# M251_v1 register map
File version: 1.0
Registers are 32-bit, read-write, reset 0x0 unless marked. A register's access mark holds for its fields unless they carry their own. Offsets are from the block's base; [hi:lo] are bit positions; {n}, {i} and the like mark numbered series.

## FMC — FMC Register Map
Base 0x4000C000
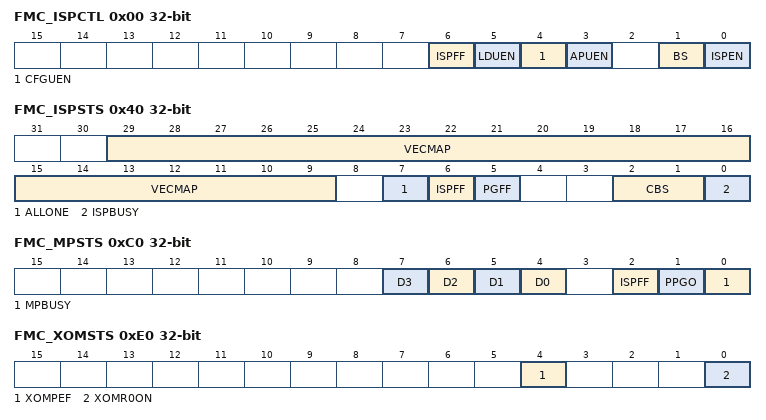
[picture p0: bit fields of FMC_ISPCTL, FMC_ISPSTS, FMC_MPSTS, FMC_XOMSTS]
0x00 FMC_ISPCTL — ISP Control Register
  [6] ISPFF — ISP Fail Flag (Write Protect). This bit is set by hardware when a triggered ISP meets any of the following conditions: This bit needs to be cleared by writing 1 to it. (1) APROM writes to itself if APUEN is set to 0. (2) LDROM writes to itself if LDUEN is set to 0. (3) CONFIG is erased/programmed if CFGUEN is set to 0. (4) Page Erase command at LOCK mode with ICE connection (5) Erase or Program command at brown-out detected (6) Destination address is illegal, such as over an available range. (7) Invalid ISP commands (8) ISP CMD in XOM region, except mass erase, page erase and chksum command (9) The wrong setting of page erase ISP CMD in XOM (10) Violate XOM setting one time protection. Note: This bit is write protected. Refer to the SYS_REGLCTL register.
  [5] LDUEN — LDROM Update Enable Bit (Write Protect). Note: This bit is write protected. Refer to the SYS_REGLCTL register.
    0=LDROM cannot be updated; 1=LDROM can be updated
  [4] CFGUEN — CONFIG Update Enable Bit (Write Protect). Note: This bit is write protected. Refer to the SYS_REGLCTL register.
    0=CONFIG cannot be updated; 1=CONFIG can be updated
  [3] APUEN — APROM Update Enable Bit (Write Protect). Note: This bit is write protected. Refer to the SYS_REGLCTL register.
    0=APROM cannot be updated when the chip runs in APROM; 1=APROM can be updated when the chip runs in APROM
  [1] BS — Boot Select (Write Protect) /clear this bit to select next booting from LDROM/APROM, respectively. This bit also functions as chip booting status flag, which can be used to check where chip booted from. This bit is initiated with the inversed value of CBS[1] (CONFIG0[7]) after any reset is happened except CPU reset or system reset is happened. Note: This bit is write protected. Refer to the SYS_REGLCTL register.
    0=Booting from APROM; 1=Booting from LDROM
  [0] ISPEN — ISP Enable Bit (Write Protect). ISP function enable bit. Set this bit to enable ISP function. Note: This bit is write protected. Refer to the SYS_REGLCTL register.
    0=ISP function Disabled; 1=ISP function Enabled
0x04 FMC_ISPADDR — ISP Address Register
  [31:0] ISPADDR — ISP Address. The NuMicro M23 series is equipped with embedded Flash. ISPADDR[1:0] must be kept 00 for ISP 32-bit operation. ISPADDR[2:0] must be kept 000 for ISP 64-bit operation. For Checksum Calculation command, this field is the Flash starting address for checksum calculation, 512 bytes alignment is necessary for checksum calculation.
0x08 FMC_ISPDAT — ISP Data Register
  [31:0] ISPDAT — ISP Data. Write data to this register before ISP program operation. Read data from this register after ISP read operation.
0x0C FMC_ISPCMD — ISP Command Register
  [6:0] CMD — ISP Command. ISP command table is shown below: The other commands are invalid.
    0=FLASH Read; 4=Read Unique ID; 8=Read Flash All-One Result; 11=Read Company ID; 12=Read Device ID; 13=Read Checksum; 33=FLASH 32-bit Program; 34=FLASH Page Erase; 38=FLASH Mass Erase; 39=FLASH Multi-Word Program; 40=Run Flash All-One Verification; 45=Run Checksum Calculation; 46=Vector Remap
0x10 FMC_ISPTRG — ISP Trigger Control Register
  [0] ISPGO — ISP Start Trigger (Write Protect). Write 1 to start ISP operation and this bit will be cleared to 0 by hardware automatically when ISP operation is finished. Note: This bit is write-protected. Refer to the SYS_REGLCTL register.
    0=ISP operation is finished; 1=ISP is progressed
0x18 FMC_FTCTL — Flash Access Time Control Register
  [9] CACHEINV — Flash Cache Invalidation (Write Protect). Note 1: Write 1 to start cache invalidation. The value will be changed to 0 once the process finishes. Note 2: This bit is write-protected. Refer to the SYS_REGLCTL register.
    0=Flash Cache Invalidation finished (default); 1=Flash Cache Invalidation
0x40 FMC_ISPSTS (reset mask 0xFFFFFFF0) — ISP Status Register
  [29:9] VECMAP ro — Vector Page Mapping Address (Read Only). All access to 0x0000_0000~0x0000_01FF is remapped to the Flash memory or SRAM address {VECMAP[20:0], 9'h000} ~ {VECMAP[20:0], 9'h1FF}. VECMAP [18:12] should be 0.
  [7] ALLONE — Flash All-one Verification Flag. This bit is set by hardware if all of Flash bits are 1, and clear if Flash bits are not all 1 after 'Run Flash All-One Verification' complete; this bit also can be clear by writing 1
    0=Flash bits are not all 1 after 'Run Flash All-One Verification' complete; 1=All of Flash bits are 1 after 'Run Flash All-One Verification' complete
  [6] ISPFF — ISP Fail Flag (Write Protect). This bit is the mirror of ISPFF (FMC_ISPCTL[6]), it needs to be cleared by writing 1 to FMC_ISPCTL[6] or FMC_ISPSTS[6]. This bit is set by hardware when a triggered ISP meets any of the following conditions: (1) APROM writes to itself if APUEN is set to 0. (2) LDROM writes to itself if LDUEN is set to 0. (3) CONFIG is erased/programmed if CFGUEN is set to 0. (4) Page Erase command at LOCK mode with ICE connection (5) Erase or Program command at brown-out detected (6) Destination address is illegal, such as over an available range. (7) Invalid ISP commands (8) ISP CMD in XOM region, except mass erase, page erase and chksum command (9) The wrong setting of page erase ISP CMD in XOM (10) Violate XOM setting one time protection. Note: This bit is write-protected. Refer to the SYS_REGLCTL register.
  [5] PGFF ro — Flash Program with Fast Verification Flag (Read Only). This bit is set if data is mismatched at ISP programming verification. This bit is clear by performing ISP Flash erase or ISP read CID operation
    0=Flash Program is success; 1=Flash Program is fail. Program data is different with data in the Flash memory
  [2:1] CBS ro — Boot Selection of CONFIG (Read Only). This bit is initiated with the CBS (CONFIG0[7:6]) after any reset is happened except CPU reset or system reset is happened.
    0=LDROM with IAP mode; 1=LDROM without IAP mode; 2=APROM with IAP mode; 3=APROM without IAP mode
  [0] ISPBUSY ro — ISP Busy Flag (Read Only). Write 1 to start ISP operation and this bit will be cleared to 0 by hardware automatically when ISP operation is finished. This bit is the mirror of ISPGO(FMC_ISPTRG[0]).
    0=ISP operation is finished; 1=ISP is progressed
0x4C FMC_CYCCTL reset 0x1 — Flash Access Cycle Control Register
  [3:0] CYCLE — Flash Access Cycle Control (Write Protect). The optimized HCLK working frequency range is 33~50 MHz. Note: This bit is write protected. Refer to the SYS_REGLCTL register.
    1=CPU access with zero wait cycle if cache hit or cache is disabled; Flash access cycle is 1;; 2=CPU access with one wait cycles if cache miss; Flash access cycle is 2;; 3=CPU access with two wait cycles if cahce miss; Flash access cycle is 3;
0x80 FMC_MPDAT0 — ISP Data0 Register
  [31:0] ISPDAT0 — ISP Data 0. This register is the first 32-bit data for 32-bit/multi-word programming, and it is also the mirror of FMC_ISPDAT, both registers keep the same data.
0x84 FMC_MPDAT1 — ISP Data1 Register
  [31:0] ISPDAT1 — ISP Data 1. This register is the second 32-bit data for multi-word programming.
0x88 FMC_MPDAT2 — ISP Data2 Register
  [31:0] ISPDAT2 — ISP Data 2. This register is the third 32-bit data for multi-word programming.
0x8C FMC_MPDAT3 — ISP Data3 Register
  [31:0] ISPDAT3 — ISP Data 3. This register is the fourth 32-bit data for multi-word programming.
0xC0 FMC_MPSTS ro — ISP Multi-program Status Register
  [n+4] D{n} (n=0..3) — ISP DATA {n} Flag (Read Only). This bit is set when FMC_MPDAT{n} is written and auto-clear to 0 when the FMC_MPDAT{n} data is programmed to Flash complete.
    0=FMC_MPDAT{n} register is empty, or program to Flash complete; 1=FMC_MPDAT{n} register has been written, and not program to Flash complete
  [2] ISPFF — ISP Fail Flag (Read Only). This bit is the mirror of ISPFF (FMC_ISPCTL[6]), it needs to be cleared by writing 1 to FMC_ISPCTL[6] or FMC_ISPSTS[6]. This bit is set by hardware when a triggered ISP meets any of the following conditions: (1) APROM writes to itself if APUEN is set to 0. (2) LDROM writes to itself if LDUEN is set to 0. (3) CONFIG is erased/programmed if CFGUEN is set to 0. (4) Page Erase command at LOCK mode with ICE connection (5) Erase or Program command at brown-out detected (6) Destination address is illegal, such as over an available range. (7) Invalid ISP commands.
  [1] PPGO — ISP Multi-program Status (Read Only)
    0=ISP multi-word program operation is not active; 1=ISP multi-word program operation is in progress
  [0] MPBUSY — ISP Multi-word Program Busy Flag (Read Only). Write 1 to start ISP Multi-Word program operation and this bit will be cleared to 0 by hardware automatically when ISP Multi-Word program operation is finished. This bit is the mirror of ISPGO(FMC_ISPTRG[0]).
    0=ISP Multi-Word program operation is finished; 1=ISP Multi-Word program operation is progressed
0xC4 FMC_MPADDR ro — ISP Multi-program Address Register
  [31:0] MPADDR — ISP Multi-word Program Address. MPADDR is the address of ISP multi-word program operation when ISPGO flag is 1. MPADDR will keep the final ISP address when ISP multi-word program is complete.
0xD0 FMC_XOMR0STS0 ro reset 0xFFFFFF — XOM Region 0 Status Register 0
  [23:0] BASE — XOM Region 0 Base Address (Page-aligned). BASE is the base address of XOM Region 0.
0xD4 FMC_XOMR0STS1 ro reset 0x1F — XOM Region 0 Status Register 1
  [8:0] SIZE — XOM Region 0 Size (Page-aligned). SIZE is the page number of XOM Region 0.
0xE0 FMC_XOMSTS ro — XOM Status Register
  [4] XOMPEF — XOM Page Erase Function Fail. XOM page erase function status. If XOMPEF is set to 1, user needs to erase XOM region again.
    0=Success; 1=Fail
  [0] XOMR0ON — XOM Region 0 On. XOM Region 0 active status.
    0=No active; 1=XOM region 0 is active
